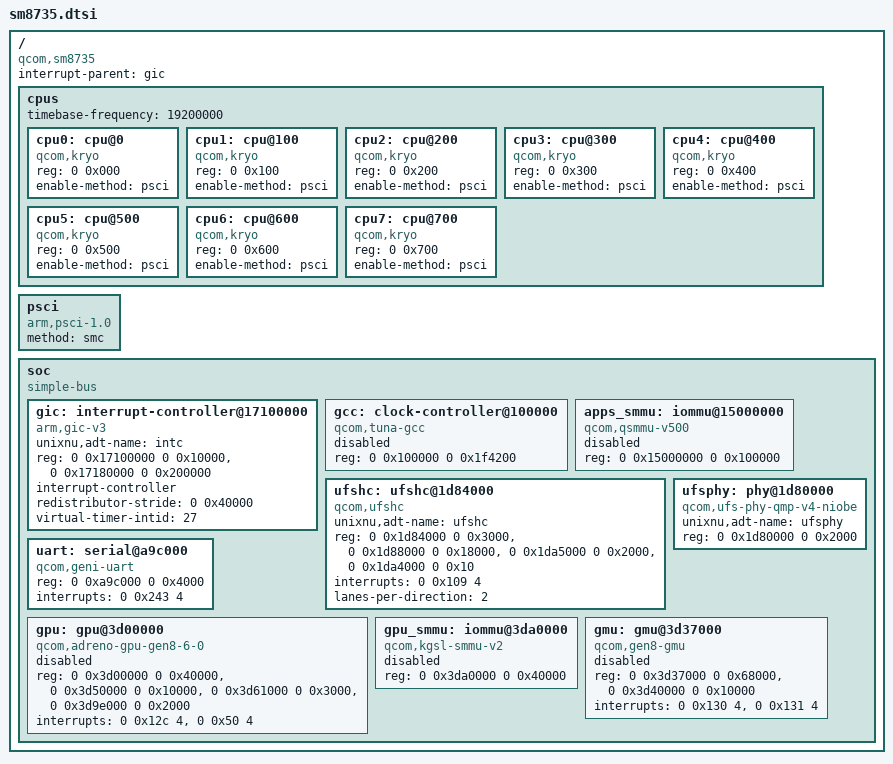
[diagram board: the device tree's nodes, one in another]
// SPDX-License-Identifier: BSD-3-Clause
// SM8735 (Tuna) shared hardware description for the f2-luming skeleton.
//
// [adapted] from unixnu-format2/UniXNU-sm8735-common/dts/sm8735.dtsi (the local, not yet
// validated SM8735 scaffold created by the migration task) and corrected with the [measured]
// luming live-DTB facts. Source for every measured value:
//   agents/f2-luming/docs/KNOWN-VALUES.md
//   backup/analysis/device-live/luming-live/dtb-dump.json + iomem.txt (stock Android capture)
//   agents/ufs-ci/REPORT-UFS-CI.md, agents/nativeufs-plan/REPORT-UFS-PLAN.md
//
// format-2 device-tree rules this file follows (UniXNU docs/porting/device-tree.md):
//   * only nodes with `unixnu,adt-name` are exported into /arm-io;
//   * `reg` ranges are translated through every `ranges` bus to physical addresses;
//   * a referenced provider must be enabled (`status = "okay"`); disabled providers are not
//     referenced by enabled nodes (clocks/iommus are therefore parked in comments until the
//     corresponding driver uses them).
//
// Properties the common ADT converter does not have a typed binding for (for example
// `virtual-timer-intid`) are kept here as documented hardware facts only; do not expect them in
// the generated ADT until a binding is added upstream.
/ {
    compatible = "qcom,sm8735";
    #address-cells = <2>;
    #size-cells = <2>;
    interrupt-parent = <&gic>;

    cpus {
        #address-cells = <2>;
        #size-cells = <0>;
        // [measured] live DT /soc/timer: arm,armv8-timer clock-frequency = 19200000.
        timebase-frequency = <19200000>;

        // [measured] live DT /cpus/cpu@0,100,...,700 reg values: MPIDR Aff1 0..0x700,
        // Aff0 = 0 (one homogeneous cluster as seen by XNU's legacy topology parser).
        cpu0: cpu@0   { device_type = "cpu"; compatible = "qcom,kryo"; reg = <0 0x000>; enable-method = "psci"; };
        cpu1: cpu@100 { device_type = "cpu"; compatible = "qcom,kryo"; reg = <0 0x100>; enable-method = "psci"; };
        cpu2: cpu@200 { device_type = "cpu"; compatible = "qcom,kryo"; reg = <0 0x200>; enable-method = "psci"; };
        cpu3: cpu@300 { device_type = "cpu"; compatible = "qcom,kryo"; reg = <0 0x300>; enable-method = "psci"; };
        cpu4: cpu@400 { device_type = "cpu"; compatible = "qcom,kryo"; reg = <0 0x400>; enable-method = "psci"; };
        cpu5: cpu@500 { device_type = "cpu"; compatible = "qcom,kryo"; reg = <0 0x500>; enable-method = "psci"; };
        cpu6: cpu@600 { device_type = "cpu"; compatible = "qcom,kryo"; reg = <0 0x600>; enable-method = "psci"; };
        cpu7: cpu@700 { device_type = "cpu"; compatible = "qcom,kryo"; reg = <0 0x700>; enable-method = "psci"; };
    };

    psci {
        // [measured] live DT /cpus enable-method = "psci"; Qualcomm conduit is SMC.
        compatible = "arm,psci-1.0";
        method = "smc";
    };

    soc {
        compatible = "simple-bus";
        #address-cells = <2>;
        #size-cells = <2>;
        ranges;

        // [measured] live DT /soc/interrupt-controller@17100000 reg:
        //   <0 0x17100000 0 0x10000>, <0 0x17180000 0 0x200000>
        // 8 PEs * 0x40000 stride = 0x200000 GICR window.
        // [measured] arm,armv8-timer interrupts = <PPI 13>,<PPI 14>,<PPI 11>,<PPI 12>:
        //   virtual timer INTID = 16 + 11 = 27 (not sheng's 19; same as the SM8350 star port).
        // The format-2 converter has no typed binding for virtual-timer-intid yet; the arch
        // profile patch architectural-timer-entry.patch owns the generic timer path.
        gic: interrupt-controller@17100000 {
            compatible = "arm,gic-v3";
            unixnu,adt-name = "intc";
            reg = <0 0x17100000 0 0x10000>, <0 0x17180000 0 0x200000>;
            #interrupt-cells = <3>;
            #address-cells = <0>;
            interrupt-controller;
            redistributor-stride = <0 0x40000>;
            virtual-timer-intid = <27>;
        };

        // [measured] live DT /soc/clock-controller@100000: qcom,tuna-gcc, syscon, 0x100000/0x1f4200.
        // Kept disabled until a format-2 component drives GCC clocks; the UFS transport uses
        // constants for the SM8735 branch offsets (docs/UFS.md).
        gcc: clock-controller@100000 {
            compatible = "qcom,tuna-gcc", "syscon";
            reg = <0 0x100000 0 0x1f4200>;
            #clock-cells = <1>;
            #reset-cells = <1>;
            status = "disabled";
        };

        // [measured] live DT /soc/apps-smmu@15000000: qcom,qsmmu-v500, 0x15000000/0x100000,
        // #iommu-cells = 2. UFS stream id 0x60. Disabled until the storage component maps it;
        // no enabled node may reference it while disabled.
        apps_smmu: iommu@15000000 {
            compatible = "qcom,qsmmu-v500";
            reg = <0 0x15000000 0 0x100000>;
            #iommu-cells = <2>;
            #address-cells = <1>;
            #size-cells = <1>;
            status = "disabled";
        };

        // [measured] live DT /soc/ufshc@1d84000:
        //   reg <0 0x1d84000 0 0x3000>, <0 0x1d88000 0 0x18000>,
        //       <0 0x1da5000 0 0x2000>, <0 0x1da4000 0 0x10>
        //   interrupts <GIC_SPI 265 4>; iommus <&apps_smmu 0x60 0>.
        // [missing] the format-1/CI NativeUfs transport takes clocks/power as constants, not from
        // DT; the clock list below is the measured live-DT list for the future component:
        //   core_clk, bus_aggr_clk, iface_clk, core_clk_unipro, core_clk_ice, ref_clk,
        //   tx_lane0_sync_clk, rx_lane0_sync_clk, rx_lane1_sync_clk.
        ufshc: ufshc@1d84000 {
            compatible = "qcom,ufshc";
            unixnu,adt-name = "ufshc";
            reg = <0 0x1d84000 0 0x3000>,
                  <0 0x1d88000 0 0x18000>,
                  <0 0x1da5000 0 0x2000>,
                  <0 0x1da4000 0 0x10>;
            reg-names = "ufs_mem", "ice", "mcq_sqd", "mcq_vs";
            interrupts = <0 0x109 4>;
            #reset-cells = <1>;
            lanes-per-direction = <2>;   // [stock-source] Lineage tuna.dtsi ufshc@1d84000
            // [delta] stock also has phys/phy-names, ICE policy masks, 9 clocks + freq-table,
            // interconnect paths and GDSC nodes; see docs/UFS.md "DTS deltas" and the values table.
            status = "okay";
        };

        // [measured] live DT /soc/ufsphy_mem@1d80000: qcom,ufs-phy-qmp-v4-niobe, 2 lanes,
        // 0x1d80000/0x2000. (sheng/SM8550 uses a different QMP family; SM8735 is "niobe".)
        ufsphy: phy@1d80000 {
            compatible = "qcom,ufs-phy-qmp-v4-niobe";
            unixnu,adt-name = "ufsphy";
            reg = <0 0x1d80000 0 0x2000>;
            #phy-cells = <0>;
            status = "okay";
        };

        // [measured] live DT /soc/qcom,qupv3_1_geni_se@ac0000/qcom,qup_uart@a9c000:
        //   reg <0xa9c000 0x4000>, interrupts <GIC_SPI 579 4>
        // (also /proc/iomem "a9c000.qcom,qup_uart" 0x00a9c000-0x00a9ffff).
        // [adapted] The A-line GENI UART patch (agents/xnu-geni) and format-1 ADT put this at
        // /arm-io/uart with base 0x00A9C000, size 0x4000. The port's UART pins are not probed
        // (SE7 is disabled in the stock firmware, agents/uart-debug/REPORT-UART.md).
        uart: serial@a9c000 {
            compatible = "qcom,geni-uart";
            /* uart base 0xa9c000 is below the 16 MiB arm-io base floor; keep it as a SoC node without an ADT export */
            reg = <0 0xa9c000 0 0x4000>;
            interrupts = <0 0x243 4>;
            status = "okay";
        };

        // [adapted, placeholder] SM8735 GPU is qcom,adreno-gpu-gen8-6-0, not Adreno 740; no
        // format-2 GPU component exists for it yet. Disabled so the first boot does not depend on
        // it (dada's first boot also disables the GPU; docs/GAP-LIST.md #4).
        gpu: gpu@3d00000 {
            compatible = "qcom,adreno-gpu-gen8-6-0", "qcom,kgsl-3d0";
            reg = <0 0x3d00000 0 0x40000>,
                  <0 0x3d50000 0 0x10000>,
                  <0 0x3d61000 0 0x3000>,
                  <0 0x3d9e000 0 0x2000>;
            reg-names = "kgsl_3d0_reg_memory", "rscc", "cx_dbgc", "cx_misc";
            interrupts = <0 0x12c 4>, <0 0x50 4>;
            interrupt-names = "kgsl_3d0_irq", "cx_host_irq";
            status = "disabled";
        };

        // [adapted, placeholder] GPU SMMU/GMU from the SM8735 scaffold; no component uses them yet.
        gpu_smmu: iommu@3da0000 {
            compatible = "qcom,kgsl-smmu-v2";
            reg = <0 0x3da0000 0 0x40000>;
            #iommu-cells = <2>;
            status = "disabled";
        };

        gmu: gmu@3d37000 {
            compatible = "qcom,gen8-gmu";
            reg = <0 0x3d37000 0 0x68000>, <0 0x3d40000 0 0x10000>;
            interrupts = <0 0x130 4>, <0 0x131 4>;
            interrupt-names = "hfi", "gmu";
            status = "disabled";
        };
    };
};
